CM_ "IMPORT _bosch_2018.dbc";

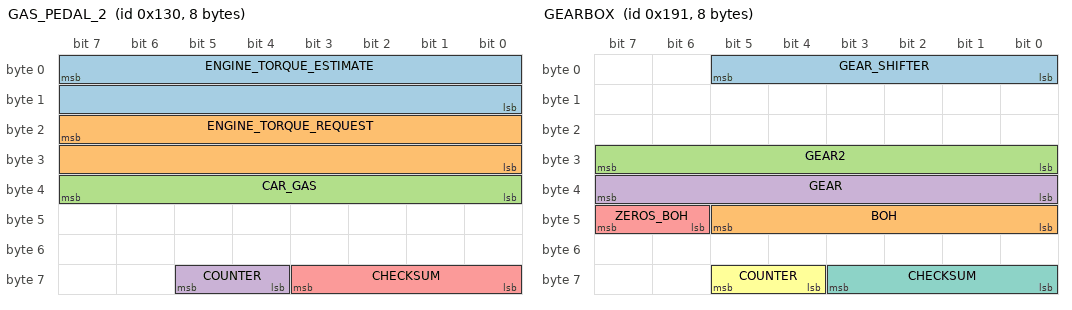
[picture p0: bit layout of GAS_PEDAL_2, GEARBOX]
BO_ 304 GAS_PEDAL_2: 8 PCM
 SG_ ENGINE_TORQUE_ESTIMATE : 7|16@0- (1,0) [-1000|1000] "Nm" EON
 SG_ ENGINE_TORQUE_REQUEST : 23|16@0- (1,0) [-1000|1000] "Nm" EON
 SG_ CAR_GAS : 39|8@0+ (1,0) [0|255] "" EON
 SG_ COUNTER : 61|2@0+ (1,0) [0|3] "" EON
 SG_ CHECKSUM : 59|4@0+ (1,0) [0|15] "" EON

BO_ 401 GEARBOX: 8 PCM
 SG_ GEAR_SHIFTER : 5|6@0+ (1,0) [0|63] "" EON
 SG_ BOH : 45|6@0+ (1,0) [0|63] "" XXX
 SG_ GEAR2 : 31|8@0+ (1,0) [0|1] "" XXX
 SG_ GEAR : 39|8@0+ (1,0) [0|255] "" XXX
 SG_ ZEROS_BOH : 47|2@0+ (1,0) [0|3] "" XXX
 SG_ COUNTER : 61|2@0+ (1,0) [0|3] "" EON
 SG_ CHECKSUM : 59|4@0+ (1,0) [0|15] "" EON

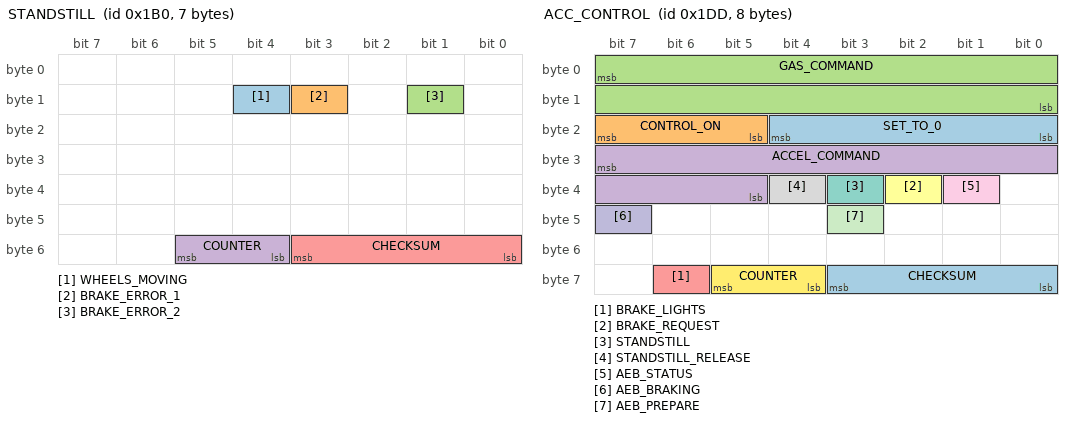
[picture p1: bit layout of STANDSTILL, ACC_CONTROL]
BO_ 432 STANDSTILL: 7 VSA
 SG_ WHEELS_MOVING : 12|1@0+ (1,0) [0|1] "" EON
 SG_ BRAKE_ERROR_1 : 11|1@0+ (1,0) [0|1] "" EON
 SG_ BRAKE_ERROR_2 : 9|1@0+ (1,0) [0|1] "" EON
 SG_ COUNTER : 53|2@0+ (1,0) [0|3] "" EON
 SG_ CHECKSUM : 51|4@0+ (1,0) [0|15] "" EON

BO_ 477 ACC_CONTROL: 8 EON
 SG_ SET_TO_0 : 20|5@0+ (1,0) [0|1] "" XXX
 SG_ CONTROL_ON : 23|3@0+ (1,0) [0|5] "" XXX
 SG_ GAS_COMMAND : 7|16@0- (1,0) [0|0] "" XXX
 SG_ ACCEL_COMMAND : 31|11@0- (0.01,0) [0|0] "m/s2" XXX
 SG_ BRAKE_LIGHTS : 62|1@0+ (1,0) [0|1] "" XXX
 SG_ BRAKE_REQUEST : 34|1@0+ (1,0) [0|1] "" XXX
 SG_ STANDSTILL : 35|1@0+ (1,0) [0|1] "" XXX
 SG_ STANDSTILL_RELEASE : 36|1@0+ (1,0) [0|1] "" XXX
 SG_ AEB_STATUS : 33|1@0+ (1,0) [0|1] "" XXX
 SG_ AEB_BRAKING : 47|1@0+ (1,0) [0|1] "" XXX
 SG_ AEB_PREPARE : 43|1@0+ (1,0) [0|1] "" XXX
 SG_ COUNTER : 61|2@0+ (1,0) [0|3] "" XXX
 SG_ CHECKSUM : 59|4@0+ (1,0) [0|15] "" XXX

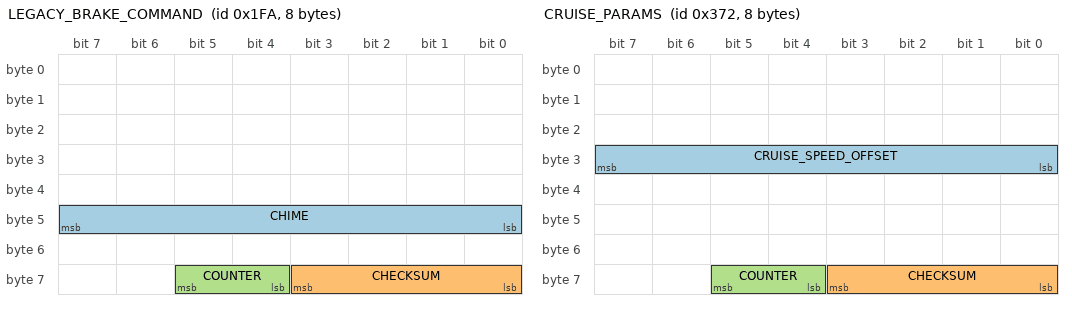
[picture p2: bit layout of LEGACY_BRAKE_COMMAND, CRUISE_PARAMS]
BO_ 506 LEGACY_BRAKE_COMMAND: 8 ADAS
 SG_ CHIME : 40|8@1+ (1,0) [0|255] "" XXX
 SG_ CHECKSUM : 59|4@0+ (1,0) [0|15] "" XXX
 SG_ COUNTER : 61|2@0+ (1,0) [0|3] "" XXX

BO_ 829 LKAS_HUD: 8 ADAS
 SG_ CAM_TEMP_HIGH : 7|1@0+ (1,0) [0|255] "" BDY
 SG_ SET_ME_X41 : 6|7@0+ (1,0) [0|127] "" BDY
 SG_ BOH : 6|7@0+ (1,0) [0|127] "" BDY
 SG_ DASHED_LANES : 14|1@0+ (1,0) [0|1] "" BDY
 SG_ DTC : 13|1@0+ (1,0) [0|1] "" BDY
 SG_ LKAS_PROBLEM : 12|1@0+ (1,0) [0|1] "" BDY
 SG_ LKAS_OFF : 11|1@0+ (1,0) [0|1] "" BDY
 SG_ SOLID_LANES : 10|1@0+ (1,0) [0|1] "" BDY
 SG_ LDW_RIGHT : 9|1@0+ (1,0) [0|1] "" BDY
 SG_ STEERING_REQUIRED : 8|1@0+ (1,0) [0|1] "" BDY
 SG_ BOH : 23|2@0+ (1,0) [0|4] "" BDY
 SG_ LDW_PROBLEM : 21|1@0+ (1,0) [0|1] "" BDY
 SG_ BEEP : 17|2@0+ (1,0) [0|1] "" BDY
 SG_ LDW_ON : 28|1@0+ (1,0) [0|1] "" BDY
 SG_ LDW_OFF : 27|1@0+ (1,0) [0|1] "" BDY
 SG_ CLEAN_WINDSHIELD : 26|1@0+ (1,0) [0|1] "" BDY
 SG_ SET_ME_X48 : 31|8@0+ (1,0) [0|255] "" BDY
 SG_ LANE_LINES : 36|2@0+ (1,0) [0|3] "" BDY
 SG_ COUNTER : 61|2@0+ (1,0) [0|3] "" BDY
 SG_ CHECKSUM : 59|4@0+ (1,0) [0|15] "" BDY

BO_ 882 CRUISE_PARAMS: 8 PCM
 SG_ CRUISE_SPEED_OFFSET : 31|8@0- (0.1,0) [-128|127] "kph" EON
 SG_ CHECKSUM : 59|4@0+ (1,0) [0|3] "" EON
 SG_ COUNTER : 61|2@0+ (1,0) [0|15] "" EON

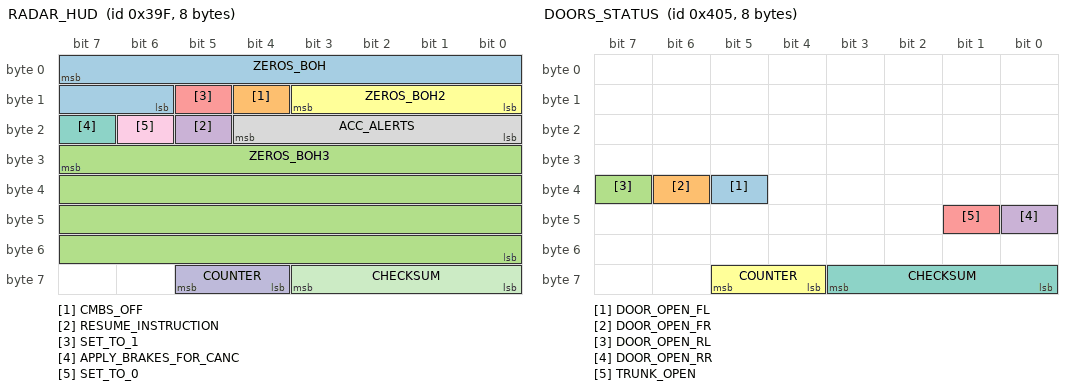
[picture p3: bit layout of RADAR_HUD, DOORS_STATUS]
BO_ 927 RADAR_HUD: 8 RADAR
 SG_ ZEROS_BOH : 7|10@0+ (1,0) [0|127] "" BDY
 SG_ CMBS_OFF : 12|1@0+ (1,0) [0|1] "" BDY
 SG_ ZEROS_BOH3 : 31|32@0+ (1,0) [0|4294967295] "" XXX
 SG_ RESUME_INSTRUCTION : 21|1@0+ (1,0) [0|1] "" XXX
 SG_ SET_TO_1 : 13|1@0+ (1,0) [0|1] "" BDY
 SG_ ZEROS_BOH2 : 11|4@0+ (1,0) [0|1] "" XXX
 SG_ APPLY_BRAKES_FOR_CANC : 23|1@0+ (1,0) [0|1] "" XXX
 SG_ ACC_ALERTS : 20|5@0+ (1,0) [0|1] "" BDY
 SG_ SET_TO_0 : 22|1@0+ (1,0) [0|1] "" XXX
 SG_ COUNTER : 61|2@0+ (1,0) [0|3] "" XXX
 SG_ CHECKSUM : 59|4@0+ (1,0) [0|15] "" XXX

BO_ 1029 DOORS_STATUS: 8 BDY
 SG_ DOOR_OPEN_FL : 37|1@0+ (1,0) [0|1] "" EON
 SG_ DOOR_OPEN_FR : 38|1@0+ (1,0) [0|1] "" EON
 SG_ DOOR_OPEN_RL : 39|1@0+ (1,0) [0|1] "" EON
 SG_ DOOR_OPEN_RR : 40|1@0+ (1,0) [0|1] "" EON
 SG_ TRUNK_OPEN : 41|1@0+ (1,0) [0|1] "" EON
 SG_ COUNTER : 61|2@0+ (1,0) [0|3] "" EON
 SG_ CHECKSUM : 59|4@0+ (1,0) [0|15] "" EON

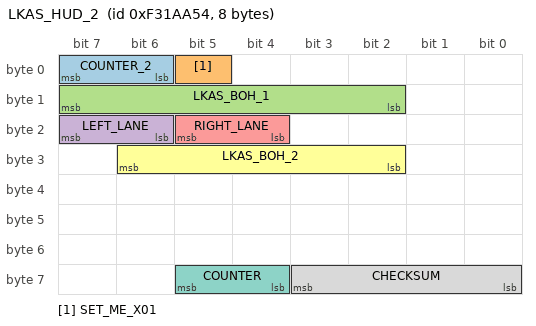
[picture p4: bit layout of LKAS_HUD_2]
BO_ 254913108 LKAS_HUD_2: 8 ADAS
 SG_ COUNTER_2 : 7|2@0+ (1,0) [0|3] "" XXX
 SG_ SET_ME_X01 : 5|1@0+ (1,0) [0|1] "" XXX
 SG_ LKAS_BOH_1 : 15|6@0+ (1,0) [0|63] "" XXX
 SG_ LEFT_LANE : 23|2@0+ (1,0) [0|3] "" XXX
 SG_ RIGHT_LANE : 21|2@0+ (1,0) [0|3] "" XXX
 SG_ LKAS_BOH_2 : 30|5@0+ (1,0) [0|31] "" XXX
 SG_ COUNTER : 61|2@0+ (1,0) [0|3] "" XXX
 SG_ CHECKSUM : 59|4@0+ (1,0) [0|15] "" XXX

VAL_ 401 GEAR_SHIFTER 32 "L" 16 "S" 8 "D" 4 "N" 2 "R" 1 "P" ;
VAL_ 401 GEAR 7 "L" 10 "S" 4 "D" 3 "N" 2 "R" 1 "P" ;
VAL_ 545 ECON_ON_2 0 "off" 3 "on" ;
VAL_ 662 CRUISE_BUTTONS 7 "tbd" 6 "tbd" 5 "tbd" 4 "accel_res" 3 "decel_set" 2 "cancel" 1 "main" 0 "none" ;
VAL_ 662 CRUISE_SETTING 3 "distance_adj" 2 "tbd" 1 "lkas_button" 0 "none" ;
VAL_ 806 CMBS_BUTTON 3 "pressed" 0 "released" ;
VAL_ 891 WIPERS 4 "High" 2 "Low" 0 "Off" ;
VAL_ 829 BEEP 3 "single_beep" 2 "triple_beep" 1 "repeated_beep" 0 "no_beep" ;

CM_ "CHFFR_METRIC 330 STEER_ANGLE STEER_ANGLE 0.36 180; CHFFR_METRIC 380 ENGINE_RPM ENGINE_RPM 1 0; CHFFR_METRIC 804 ENGINE_TEMPERATURE ENGINE_TEMPERATURE 1 0";
